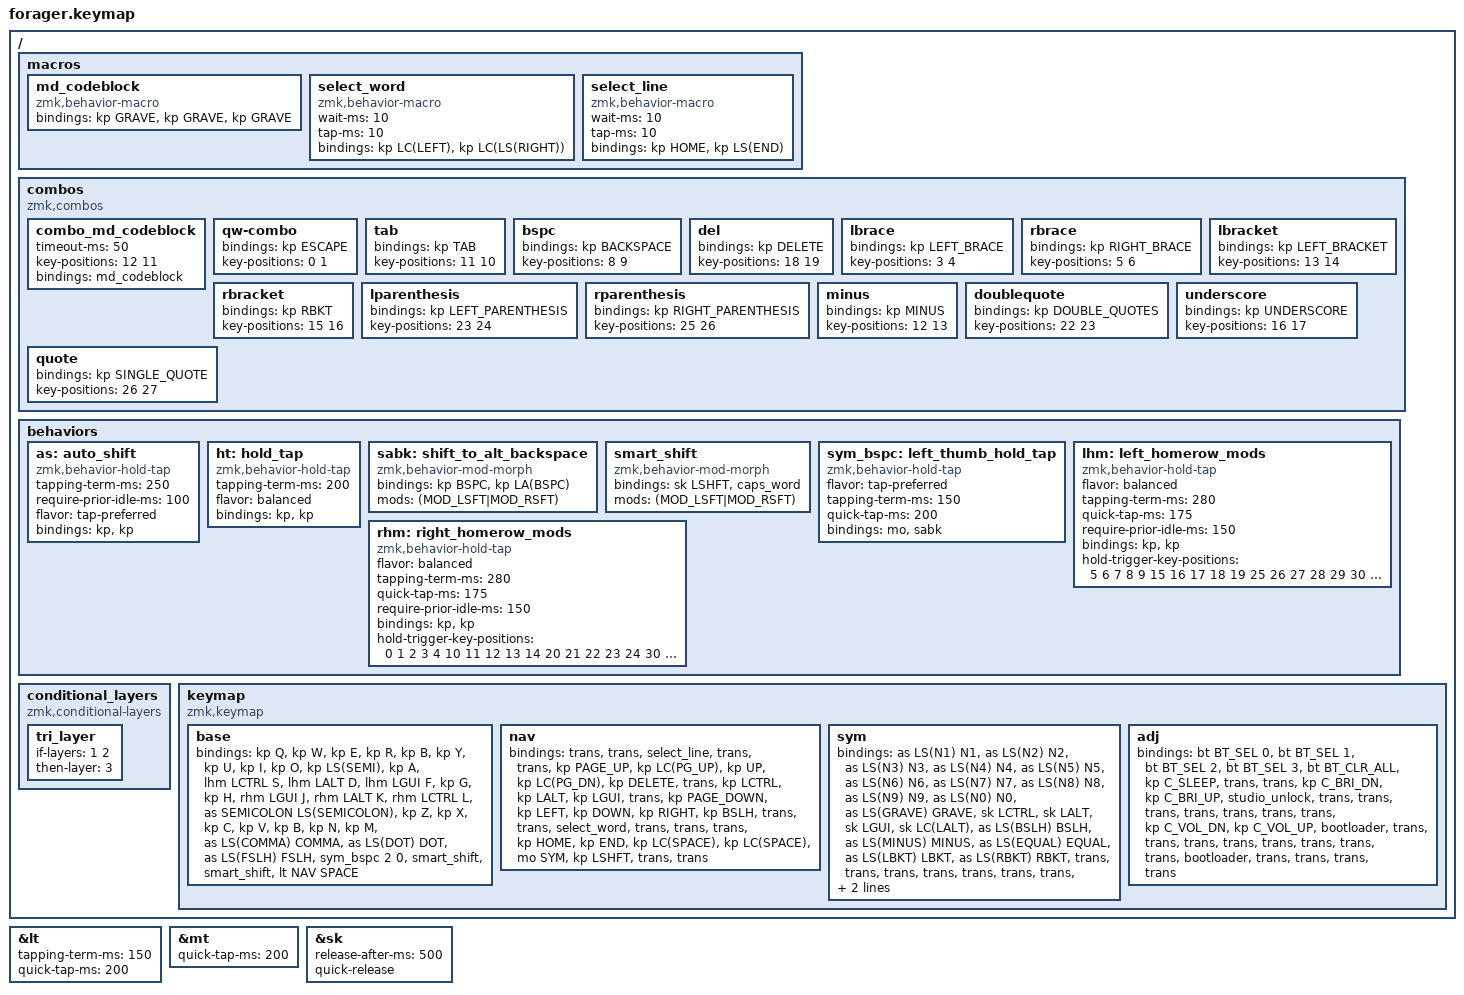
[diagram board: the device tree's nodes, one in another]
#include <behaviors.dtsi>
#include <dt-bindings/zmk/bt.h>
#include <dt-bindings/zmk/keys.h>

#define BASE 0
#define NAV  1
#define SYM  2
#define ADJ  3

/ {
    macros {
        md_codeblock: md_codeblock {
            compatible = "zmk,behavior-macro";
            #binding-cells = <0>;
            bindings = <&kp GRAVE &kp GRAVE &kp GRAVE>;
        };

        select_word: select_word {
            compatible = "zmk,behavior-macro";
            #binding-cells = <0>;
            wait-ms = <10>;
            tap-ms = <10>;

            // Windows/Linux: Ctrl+Left (start of word) -> Ctrl+Shift+Right (select word)

            bindings = <&kp LC(LEFT) &kp LC(LS(RIGHT))>;
        };

        select_line: select_line {
            compatible = "zmk,behavior-macro";
            #binding-cells = <0>;
            wait-ms = <10>;
            tap-ms = <10>;

            // Windows/Linux: Home (start of line) -> Shift+End (select line)

            bindings = <&kp HOME &kp LS(END)>;
        };
    };

    combos {
        compatible = "zmk,combos";

        combo_md_codeblock {
            timeout-ms = <50>;
            key-positions = <12 11>; // This maps to the W and F keys
            bindings = <&md_codeblock>;
        };

        qw-combo {
            bindings = <&kp ESCAPE>;
            key-positions = <0 1>;
        };

        tab {
            bindings = <&kp TAB>;
            key-positions = <11 10>;
        };

        bspc {
            bindings = <&kp BACKSPACE>;
            key-positions = <8 9>;
        };

        del {
            bindings = <&kp DELETE>;
            key-positions = <18 19>;
        };

        lbrace {
            bindings = <&kp LEFT_BRACE>;
            key-positions = <3 4>;
        };

        rbrace {
            bindings = <&kp RIGHT_BRACE>;
            key-positions = <5 6>;
        };

        lbracket {
            bindings = <&kp LEFT_BRACKET>;
            key-positions = <13 14>;
        };

        rbracket {
            bindings = <&kp RBKT>;
            key-positions = <15 16>;
        };

        lparenthesis {
            bindings = <&kp LEFT_PARENTHESIS>;
            key-positions = <23 24>;
        };

        rparenthesis {
            bindings = <&kp RIGHT_PARENTHESIS>;
            key-positions = <25 26>;
        };

        minus {
            bindings = <&kp MINUS>;
            key-positions = <12 13>;
        };

        doublequote {
            bindings = <&kp DOUBLE_QUOTES>;
            key-positions = <22 23>;
        };

        underscore {
            bindings = <&kp UNDERSCORE>;
            key-positions = <16 17>;
        };

        quote {
            bindings = <&kp SINGLE_QUOTE>;
            key-positions = <26 27>;
        };
    };
};

/ {
    behaviors {
        as: auto_shift {
            compatible = "zmk,behavior-hold-tap";
            #binding-cells = <2>;
            tapping-term-ms = <250>;
            require-prior-idle-ms = <100>;
            flavor = "tap-preferred";
            bindings = <&kp>, <&kp>;
        };

        ht: hold_tap {
            compatible = "zmk,behavior-hold-tap";
            #binding-cells = <2>;
            tapping-term-ms = <200>;
            flavor = "balanced";
            bindings = <&kp>, <&kp>;
        };

        sabk: shift_to_alt_backspace {
            compatible = "zmk,behavior-mod-morph";
            #binding-cells = <0>;
            bindings = <&kp BSPC>, <&kp LA(BSPC)>;

            mods = <(MOD_LSFT|MOD_RSFT)>;
        };

        smart_shift: smart_shift {
            compatible = "zmk,behavior-mod-morph";
            #binding-cells = <0>;
            bindings = <&sk LSHFT>, <&caps_word>;

            mods = <(MOD_LSFT|MOD_RSFT)>;
        };

        sym_bspc: left_thumb_hold_tap {
            compatible = "zmk,behavior-hold-tap";
            #binding-cells = <2>;
            flavor = "tap-preferred";
            tapping-term-ms = <150>;
            quick-tap-ms = <200>;
            bindings = <&mo>, <&sabk>;
        };

        lhm: left_homerow_mods {
            compatible = "zmk,behavior-hold-tap";
            #binding-cells = <2>;
            flavor = "balanced";
            tapping-term-ms = <280>;
            quick-tap-ms = <175>;
            require-prior-idle-ms = <150>;
            bindings = <&kp>, <&kp>;

            hold-trigger-key-positions = <5 6 7 8 9 15 16 17 18 19 25 26 27 28 29 30 31 32 33>;
        };

        rhm: right_homerow_mods {
            compatible = "zmk,behavior-hold-tap";
            #binding-cells = <2>;
            flavor = "balanced";
            tapping-term-ms = <280>;
            quick-tap-ms = <175>;
            require-prior-idle-ms = <150>;
            bindings = <&kp>, <&kp>;

            hold-trigger-key-positions = <0 1 2 3 4 10 11 12 13 14 20 21 22 23 24 30 31 32 33>;
        };
    };

    conditional_layers {
        compatible = "zmk,conditional-layers";

        tri_layer {
            if-layers = <1 2>;
            then-layer = <3>;
        };
    };

    keymap {
        compatible = "zmk,keymap";

        base {
            bindings = <
&kp Q  &kp W  &kp E  &kp R  &kp B  &kp Y  &kp U  &kp I  &kp O  &kp LS(SEMI)  &kp A  &lhm LCTRL S  &lhm LALT D  &lhm LGUI F  &kp G  &kp H  &rhm LGUI J  &rhm LALT K  &rhm LCTRL L  &as SEMICOLON LS(SEMICOLON)  &kp Z  &kp X  &kp C  &kp V  &kp B  &kp N  &kp M  &as LS(COMMA) COMMA  &as LS(DOT) DOT  &as LS(FSLH) FSLH  &sym_bspc 2 0  &smart_shift  &smart_shift  &lt NAV SPACE
            >;
        };

        nav {
            bindings = <
&trans  &trans  &select_line  &trans  &trans  &kp PAGE_UP  &kp LC(PG_UP)  &kp UP  &kp LC(PG_DN)  &kp DELETE  &trans  &kp LCTRL  &kp LALT  &kp LGUI  &trans  &kp PAGE_DOWN  &kp LEFT  &kp DOWN  &kp RIGHT  &kp BSLH  &trans  &trans  &select_word  &trans  &trans  &trans  &kp HOME  &kp END  &kp LC(SPACE)  &kp LC(SPACE)  &mo SYM  &kp LSHFT  &trans  &trans
            >;
        };

        sym {
            bindings = <
&as LS(N1) N1  &as LS(N2) N2  &as LS(N3) N3  &as LS(N4) N4  &as LS(N5) N5  &as LS(N6) N6  &as LS(N7) N7  &as LS(N8) N8  &as LS(N9) N9  &as LS(N0) N0  &as LS(GRAVE) GRAVE  &sk LCTRL  &sk LALT  &sk LGUI  &sk LC(LALT)  &as LS(BSLH) BSLH  &as LS(MINUS) MINUS  &as LS(EQUAL) EQUAL  &as LS(LBKT) LBKT  &as LS(RBKT) RBKT  &trans  &trans  &trans  &trans  &trans  &trans  &trans  &trans  &trans  &kp ENTER  &trans  &trans  &kp LSHFT  &mo NAV
            >;
        };

        adj {
            bindings = <
&bt BT_SEL 0  &bt BT_SEL 1  &bt BT_SEL 2  &bt BT_SEL 3  &bt BT_CLR_ALL  &kp C_SLEEP  &trans  &trans  &kp C_BRI_DN  &kp C_BRI_UP  &studio_unlock  &trans  &trans  &trans  &trans  &trans  &trans  &trans  &kp C_VOL_DN  &kp C_VOL_UP  &bootloader  &trans  &trans  &trans  &trans  &trans  &trans  &trans  &trans  &bootloader  &trans  &trans  &trans  &trans
            >;
        };
    };
};

&lt {
    tapping-term-ms = <150>;
    quick-tap-ms = <200>;
};

&mt { quick-tap-ms = <200>; };

&sk {
    release-after-ms = <500>;
    quick-release;
};
